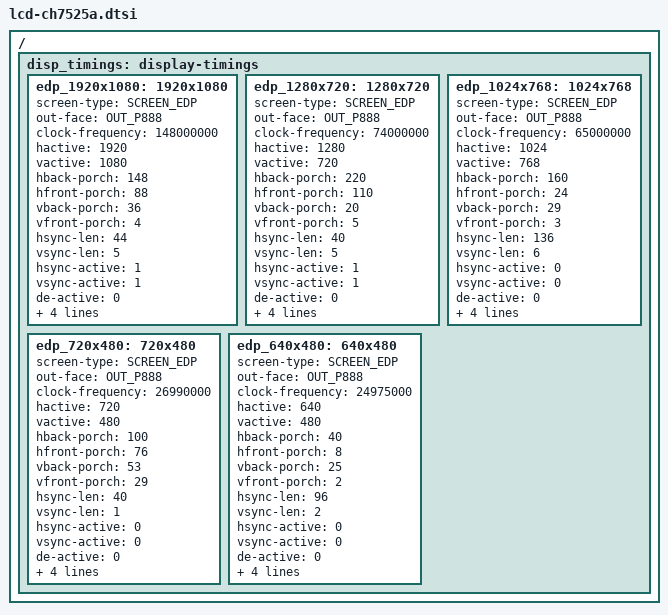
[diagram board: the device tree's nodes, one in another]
/*
 * Advantech. eDP to hdmi chip ch7525a
 *
 */

/ {
	disp_timings: display-timings {
		edp_1920x1080: 1920x1080 {
			screen-type = <SCREEN_EDP>;
			out-face    = <OUT_P888>;
			clock-frequency = <148000000>;
			hactive = <1920>;
			vactive = <1080>;
			hback-porch = <148>;
			hfront-porch = <88>;
			vback-porch = <36>;
			vfront-porch = <4>;
			hsync-len = <44>;
			vsync-len = <5>;
			hsync-active = <1>;
			vsync-active = <1>;
			de-active = <0>;
			pixelclk-active = <1>;
			swap-rb = <0>;
			swap-rg = <0>;
			swap-gb = <0>;
		};
		edp_1280x720: 1280x720 {
			screen-type = <SCREEN_EDP>;
			out-face    = <OUT_P888>;
			clock-frequency = <74000000>;
			hactive = <1280>;
			vactive = <720>;
			hback-porch = <220>;
			hfront-porch = <110>;
			vback-porch = <20>;
			vfront-porch = <5>;
			hsync-len = <40>;
			vsync-len = <5>;
			hsync-active = <1>;
			vsync-active = <1>;
			de-active = <0>;
			pixelclk-active = <1>;
			swap-rb = <0>;
			swap-rg = <0>;
			swap-gb = <0>;
		};
		edp_1024x768: 1024x768 {
			screen-type = <SCREEN_EDP>;
			out-face    = <OUT_P888>;
			clock-frequency = <65000000>;
			hactive = <1024>;
			vactive = <768>;
			hback-porch = <160>;
			hfront-porch = <24>;
			vback-porch = <29>;
			vfront-porch = <3>;
			hsync-len = <136>;
			vsync-len = <6>;
			hsync-active = <0>;
			vsync-active = <0>;
			de-active = <0>;
			pixelclk-active = <1>;
			swap-rb = <0>;
			swap-rg = <0>;
			swap-gb = <0>;
		};
		edp_720x480: 720x480 {
			screen-type = <SCREEN_EDP>;
			out-face    = <OUT_P888>;
			clock-frequency = <26990000>;
			hactive = <720>;
			vactive = <480>;
			hback-porch = <100>;
			hfront-porch = <76>;
			vback-porch = <53>;
			vfront-porch = <29>;
			hsync-len = <40>;
			vsync-len = <1>;
			hsync-active = <0>;
			vsync-active = <0>;
			de-active = <0>;
			pixelclk-active = <1>;
			swap-rb = <0>;
			swap-rg = <0>;
			swap-gb = <0>;
		};
		edp_640x480: 640x480 {
			screen-type = <SCREEN_EDP>;
			out-face    = <OUT_P888>;
			clock-frequency = <24975000>;
			hactive = <640>;
			vactive = <480>;
			hback-porch = <40>;
			hfront-porch = <8>;
			vback-porch = <25>;
			vfront-porch = <2>;
			hsync-len = <96>;
			vsync-len = <2>;
			hsync-active = <0>;
			vsync-active = <0>;
			de-active = <0>;
			pixelclk-active = <1>;
			swap-rb = <0>;
			swap-rg = <0>;
			swap-gb = <0>;
		};
	};
};
